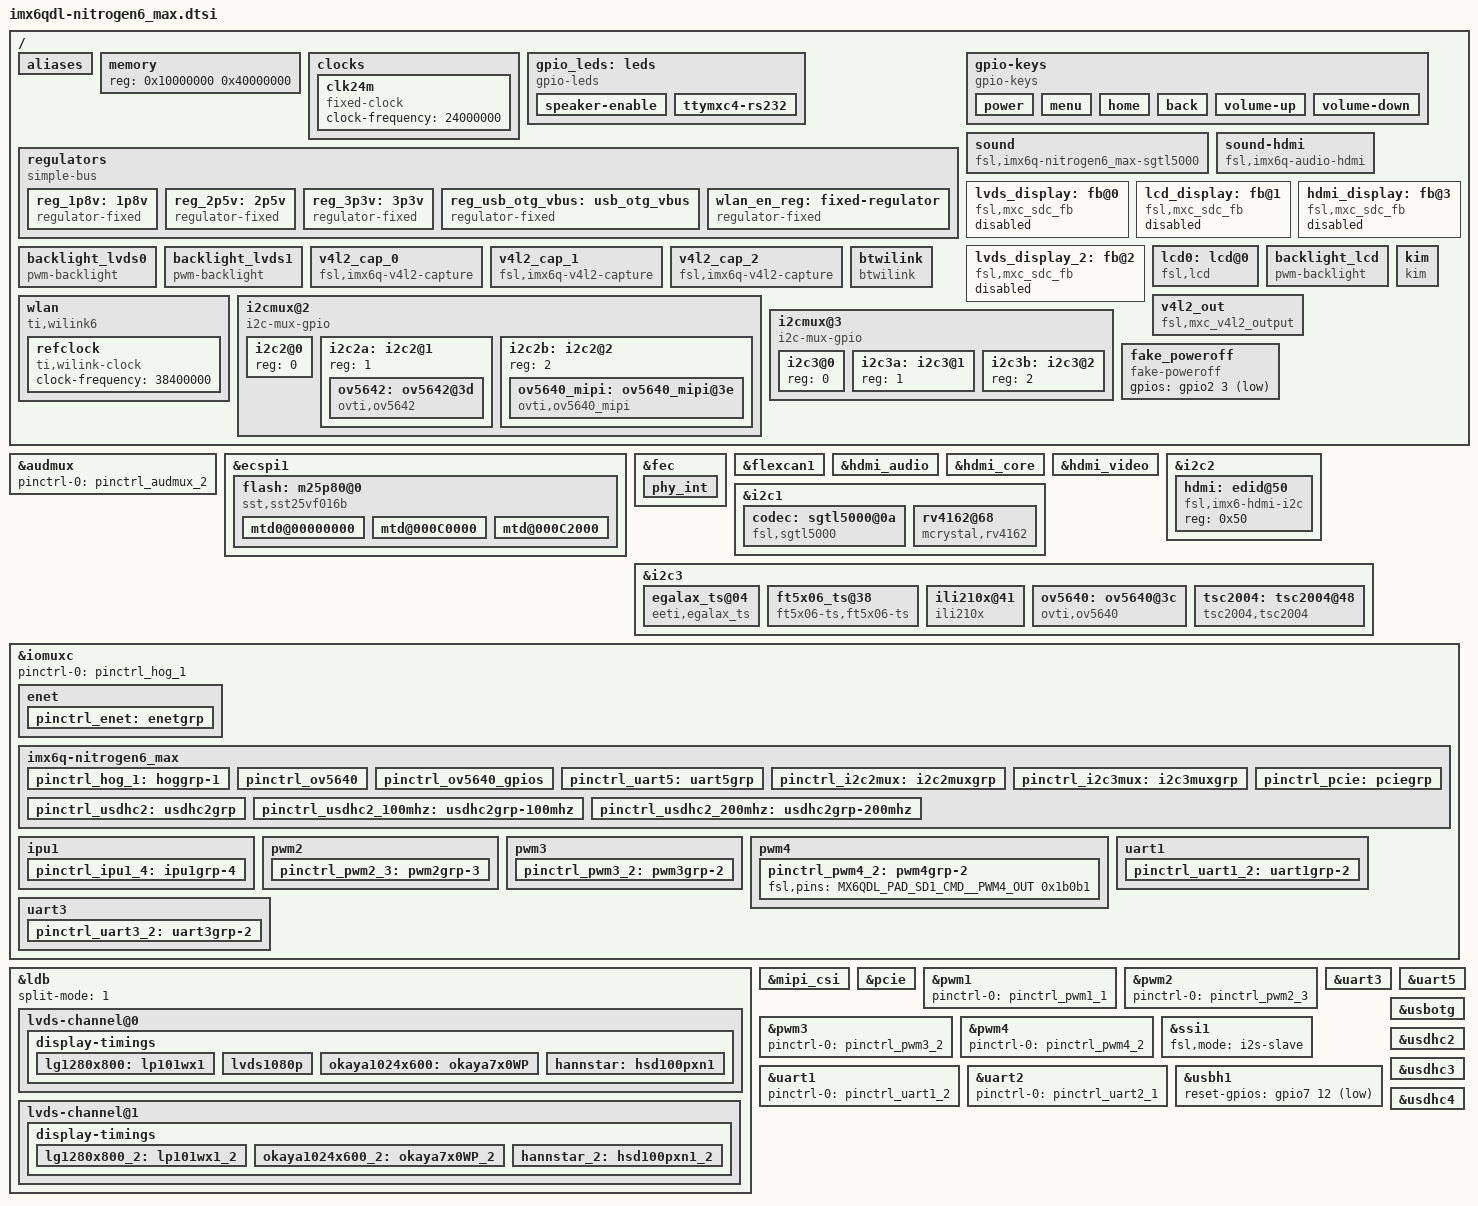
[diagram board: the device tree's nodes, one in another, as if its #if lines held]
/*
 * Copyright 2013 Boundary Devices
 * Copyright 2012 Freescale Semiconductor, Inc.
 * Copyright 2011 Linaro Ltd.
 *
 * The code contained herein is licensed under the GNU General Public
 * License. You may obtain a copy of the GNU General Public License
 * Version 2 or later at the following locations:
 *
 * http://www.opensource.org/licenses/gpl-license.html
 * http://www.gnu.org/copyleft/gpl.html
 */
#include <dt-bindings/input/input.h>

/ {
	aliases {
                mxcfb0 = &hdmi_display;
                mxcfb1 = &lvds_display;
                mxcfb2 = &lcd_display;
                mxcfb3 = &lvds_display_2;
		hdmi_display = &hdmi_display;
		lvds_display = &lvds_display;
		lcd_display = &lcd_display;
		hannstar = &hannstar ;
		lg1280x800 = &lg1280x800;
		lvds1080p = &lvds1080p;
		okaya1024x600 = &okaya1024x600;

		lvds_display_2 = &lvds_display_2;
		hannstar_2 = &hannstar_2 ;
		lg1280x800_2 = &lg1280x800_2;
		okaya1024x600_2 = &okaya1024x600_2;
		ldb = &ldb;
	};

	memory {
		reg = <0x10000000 0x40000000>;
	};

	clocks {
		clk24m: clk24m {
			compatible = "fixed-clock";
			#clock-cells = <0>;
			clock-frequency = <24000000>;
		};
	};

	gpio_leds: leds {
		compatible = "gpio-leds";
	};

	regulators {
		compatible = "simple-bus";

		reg_1p8v: 1p8v {
			compatible = "regulator-fixed";
			regulator-name = "1P8V";
			regulator-min-microvolt = <1800000>;
			regulator-max-microvolt = <1800000>;
			regulator-always-on;
		};

		reg_2p5v: 2p5v {
			compatible = "regulator-fixed";
			regulator-name = "2P5V";
			regulator-min-microvolt = <2500000>;
			regulator-max-microvolt = <2500000>;
			regulator-always-on;
		};

		reg_3p3v: 3p3v {
			compatible = "regulator-fixed";
			regulator-name = "3P3V";
			regulator-min-microvolt = <3300000>;
			regulator-max-microvolt = <3300000>;
			regulator-always-on;
		};

		reg_usb_otg_vbus: usb_otg_vbus {
			compatible = "regulator-fixed";
			regulator-name = "usb_otg_vbus";
			regulator-min-microvolt = <5000000>;
			regulator-max-microvolt = <5000000>;
			gpio = <&gpio3 22 0>;
			enable-active-high;
		};

		wlan_en_reg: fixed-regulator {
			compatible = "regulator-fixed";
			regulator-name = "wlan-en";
			regulator-min-microvolt = <3300000>;
			regulator-max-microvolt = <3300000>;

			gpio = <&gpio6 15 0>;
			startup-delay-us = <70000>;
			enable-active-high;
			debug;
		};
	};

	gpio-keys {
		compatible = "gpio-keys";
		power {
			label = "Power Button";
			gpios = <&gpio2 3 GPIO_ACTIVE_LOW>;
			linux,code = <KEY_POWER>;	/* or KEY_SEARCH */
			gpio-key,wakeup;
		};

		menu {
			label = "Menu";
			gpios = <&gpio2 1 GPIO_ACTIVE_LOW>;
			linux,code = <KEY_MENU>;
		};

		home {
			label = "Home";
			gpios = <&gpio2 4 GPIO_ACTIVE_LOW>;
			linux,code = <KEY_HOME>;
		};

		back {
			label = "Back";
			gpios = <&gpio2 2 GPIO_ACTIVE_LOW>;
			linux,code = <KEY_BACK>;
		};

		volume-up {
			label = "Volume Up";
			gpios = <&gpio7 13 GPIO_ACTIVE_LOW>;
			linux,code = <KEY_VOLUMEUP>;
		};

		volume-down {
			label = "Volume Down";
			gpios = <&gpio7 1 GPIO_ACTIVE_LOW>;
			linux,code = <KEY_VOLUMEDOWN>;
		};
	};

	sound {
		compatible = "fsl,imx6q-nitrogen6_max-sgtl5000",
			     "fsl,imx-audio-sgtl5000";
		model = "sgtl5000-audio";
		cpu-dai = <&ssi1>;
		audio-codec = <&codec>;
		audio-routing =
			"MIC_IN", "Mic Jack",
			"Mic Jack", "Mic Bias",
			"Headphone Jack", "HP_OUT";
		mux-int-port = <1>;
		mux-ext-port = <3>;
	};
	sound-hdmi {
		compatible = "fsl,imx6q-audio-hdmi",
			     "fsl,imx-audio-hdmi";
		model = "imx-audio-hdmi";
		hdmi-controller = <&hdmi_audio>;
	};

	lvds_display: fb@0 {
		compatible = "fsl,mxc_sdc_fb";
		disp_dev = "ldb";
		interface_pix_fmt = "RGB666";
		default_bpp = <16>;
		int_clk = <0>;
		late_init = <0>;
		status = "disabled";
	};

	lcd_display: fb@1 {
		compatible = "fsl,mxc_sdc_fb";
		disp_dev = "lcd";
		interface_pix_fmt = "RGB666";
		default_bpp = <16>;
		int_clk = <0>;
		late_init = <0>;
		status = "disabled";
	};

	lvds_display_2: fb@2 {
		compatible = "fsl,mxc_sdc_fb";
		disp_dev = "ldb";
		interface_pix_fmt = "RGB666";
		default_bpp = <16>;
		int_clk = <0>;
		late_init = <0>;
		status = "disabled";
	};

	hdmi_display: fb@3 {
		compatible = "fsl,mxc_sdc_fb";
		disp_dev = "hdmi";
		interface_pix_fmt = "RGB24";
		mode_str ="1280x720M@60";
		default_bpp = <24>;
		int_clk = <0>;
		late_init = <0>;
		status = "disabled";
	};

	lcd0: lcd@0 {
		compatible = "fsl,lcd";
		ipu_id = <0>;
		disp_id = <0>;
		default_ifmt = "RGB666";
		pinctrl-names = "default";
		pinctrl-0 = <&pinctrl_ipu1_4>;
		status = "okay";
	};

	backlight_lcd: backlight_lcd {
		compatible = "pwm-backlight";
		pwms = <&pwm1 0 5000000>;
		brightness-levels = <0 4 8 16 32 64 128 255>;
		default-brightness-level = <7>;
	};

	backlight_lvds0 {
		compatible = "pwm-backlight";
		pwms = <&pwm4 0 5000000>;
		brightness-levels = <0 4 8 16 32 64 128 255>;
		default-brightness-level = <7>;
	};

	backlight_lvds1: backlight_lvds1 {
		compatible = "pwm-backlight";
		pwms = <&pwm2 0 5000000>;
		brightness-levels = <0 4 8 16 32 64 128 255>;
		default-brightness-level = <7>;
	};

	v4l2_cap_0 {
		compatible = "fsl,imx6q-v4l2-capture";
		ipu_id = <0>;
		csi_id = <0>;
		mclk_source = <0>;
		status = "okay";
	};

	v4l2_cap_1 {
		compatible = "fsl,imx6q-v4l2-capture";
		ipu_id = <0>;
		csi_id = <1>;
		mipi_camera = <1>;
		mclk_source = <0>;
		status = "okay";
	};

	v4l2_cap_2: v4l2_cap_2 {
		compatible = "fsl,imx6q-v4l2-capture";
		ipu_id = <0>;
		csi_id = <1>;
		mclk_source = <0>;
		status = "okay";
	};

	v4l2_out {
		compatible = "fsl,mxc_v4l2_output";
		status = "okay";
	};
#ifdef CONFIG_WL_TI
	wlan {
		compatible = "ti,wilink6";
		interrupt-parent = <&gpio6>;
		interrupts = <11 IRQ_TYPE_LEVEL_HIGH>;
		clocks = <&refclock>;
		clock-names = "refclock";

		refclock: refclock {
			compatible = "ti,wilink-clock";
			#clock-cells = <0>;
			clock-frequency = <38400000>;
		};
	};

	btwilink {
		compatible = "btwilink";
	};

	kim {
		compatible = "kim";
		nshutdown_gpio = <&gpio6 16 0>;
		dev_name = "/dev/ttymxc2";
		flow_cntrl = <1>;
		baud_rate = <3000000>;
	};
#else
	bt_rfkill: bt_rfkill {
		compatible = "net,rfkill-gpio";
		name = "bt_rfkill";
		gpios = <&gpio6 16 0>;
		type = <2>;     /* bluetooth */
	};
#endif
	i2cmux@2 {
		compatible = "i2c-mux-gpio";
		pinctrl-names = "default";
		pinctrl-0 = <&pinctrl_i2c2mux>;
		#address-cells = <1>;
		#size-cells = <0>;
		mux-gpios = <&gpio3 20 0>, <&gpio4 15 0>;
		i2c-parent = <&i2c2>;
		idle-state = <0>;

		i2c2@0 {
			reg = <0>;
			#address-cells = <1>;
			#size-cells = <0>;
		};

		i2c2a: i2c2@1 {
			reg = <1>;
			#address-cells = <1>;
			#size-cells = <0>;
		};

		i2c2b: i2c2@2 {
			reg = <2>;
			#address-cells = <1>;
			#size-cells = <0>;
		};
	};

	i2cmux@3 {
		compatible = "i2c-mux-gpio";
		pinctrl-names = "default";
		pinctrl-0 = <&pinctrl_i2c3mux>;
		#address-cells = <1>;
		#size-cells = <0>;
		mux-gpios = <&gpio2 25 0>;
		i2c-parent = <&i2c3>;
		idle-state = <0>;

		i2c3@0 {
			reg = <0>;
			#address-cells = <1>;
			#size-cells = <0>;
		};

		i2c3a: i2c3@1 {
			reg = <1>;
			#address-cells = <1>;
			#size-cells = <0>;
		};

		i2c3b: i2c3@2 {
			reg = <2>;
			#address-cells = <1>;
			#size-cells = <0>;
		};
	};

	fake_poweroff {
		compatible = "fake-poweroff";
		gpios = <&gpio2 3 GPIO_ACTIVE_LOW>;
	};
};

&audmux {
	pinctrl-names = "default";
	pinctrl-0 = <&pinctrl_audmux_2>;
	status = "okay";
};

&ecspi1 {
	fsl,spi-num-chipselects = <1>;
	cs-gpios = <&gpio3 19 0>;
	pinctrl-names = "default";
	pinctrl-0 = <&pinctrl_ecspi1_1>;
	status = "okay";

	flash: m25p80@0 {
		compatible = "sst,sst25vf016b";
		spi-max-frequency = <20000000>;
		reg = <0>;
		#address-cells = <1>;
		#size-cells = <1>;
		mtd0@00000000 {
			label = "U-Boot";
			reg = <0x0 0xC0000>;
		};

		mtd@000C0000 {
			label = "env";
			reg = <0xC0000 0x2000>;
		};
		mtd@000C2000 {
			label = "splash";
			reg = <0xC2000 0x13e000>;
		};
	};
};

&fec {
	pinctrl-names = "default";
	pinctrl-0 = <&pinctrl_enet>;
	phy-mode = "rgmii";
#if 0
	phy-reset-gpios = <&gpio1 27 0>;
	status = "okay";
#endif
	interrupts-extended = <&gpio1 6 IRQ_TYPE_LEVEL_HIGH>,
			      <&intc 0 119 IRQ_TYPE_LEVEL_HIGH>;
	status = "okay";

	#address-cells = <0>;
	#size-cells = <1>;
	phy_int {
		reg = <0x6>;
		interrupt-parent = <&gpio1>;
		interrupts = <28 IRQ_TYPE_LEVEL_LOW>;
	};
};

&flexcan1 {
	pinctrl-names = "default";
	pinctrl-0 = <&pinctrl_flexcan1_1>;
	trx-stby-gpio = <&gpio1 2 GPIO_ACTIVE_LOW>;
	status = "okay";
};

&gpio_leds {
	speaker-enable {
		gpios = <&gpio1 29 GPIO_ACTIVE_HIGH>;
		retain-state-suspended;
		default-state = "off";
	};
	ttymxc4-rs232 {
		gpios = <&gpio6 10 GPIO_ACTIVE_HIGH>;
		retain-state-suspended;
		default-state = "on";
	};
};

&hdmi_audio {
	status = "okay";
};

&hdmi_core {
	ipu_id = <1>;
	disp_id = <0>;
	status = "okay";
};

&hdmi_video {
	fsl,phy_reg_vlev = <0x0294>;
	fsl,phy_reg_cksymtx = <0x800d>;
	status = "okay";
};

&i2c1 {
	clock-frequency = <100000>;
	pinctrl-names = "default";
	pinctrl-0 = <&pinctrl_i2c1_1>;
	status = "okay";

	codec: sgtl5000@0a {
		compatible = "fsl,sgtl5000";
		reg = <0x0a>;
		clocks = <&clks 201>;
		VDDA-supply = <&reg_2p5v>;
		VDDIO-supply = <&reg_3p3v>;
	};
	rv4162@68 {
		compatible = "mcrystal,rv4162";
		reg = <0x68>;
		interrupt-parent = <&gpio4>;
		interrupts = <6 IRQ_TYPE_LEVEL_LOW>;
	};
};

&i2c2 {
	clock-frequency = <100000>;
	pinctrl-names = "default";
	pinctrl-0 = <&pinctrl_i2c2_2>;
	status = "okay";

	hdmi: edid@50 {
		compatible = "fsl,imx6-hdmi-i2c";
		reg = <0x50>;
	};
};

&i2c2a {
	ov5642: ov5642@3d {
		compatible = "ovti,ov5642";
		reg = <0x3d>;
		pinctrl-names = "default";
		pinctrl-0 = <&pinctrl_ipu1_2>;
		clocks = <&clks 200>;
		clock-names = "csi_mclk";
		DOVDD-supply = <&reg_1p8v>;
		AVDD-supply = <&reg_2p5v>;
		DVDD-supply = <&reg_1p8v>;
		pwn-gpios = <&gpio3 29 1>;
		rst-gpios = <&gpio1 4 0>;
		ipu_id = <0>;
		csi_id = <0>;
		mclk = <24000000>;
		mclk_source = <0>;
	};
};

&i2c2b {
	ov5640_mipi: ov5640_mipi@3e {
		compatible = "ovti,ov5640_mipi";
		reg = <0x3e>;
		clocks = <&clks 147>;
		clock-names = "csi_mclk";
		DOVDD-supply = <&reg_1p8v>;
		AVDD-supply = <&reg_2p5v>;
		DVDD-supply = <&reg_1p8v>;
		pwn-gpios = <&gpio6 9 1>;
		rst-gpios = <&gpio2 5 0>;
		ipu_id = <0>;
		csi_id = <1>;
		mclk = <22000000>;
		mclk_source = <0>;
		pwms = <&pwm3 0 45>;
	};
};

&i2c3 {
        clock-frequency = <100000>;
        pinctrl-names = "default";
        pinctrl-0 = <&pinctrl_i2c3_3>;
        status = "okay";

        egalax_ts@04 {
                compatible = "eeti,egalax_ts";
                reg = <0x04>;
                interrupt-parent = <&gpio1>;
                interrupts = <9 2>;
                wakeup-gpios = <&gpio1 9 0>;
        };

        ft5x06_ts@38 {
		compatible = "ft5x06-ts,ft5x06-ts";
		reg = <0x38>;
		interrupt-parent = <&gpio1>;
		interrupts = <9 2>;
		wakeup-gpios = <&gpio1 9 0>;
	};

        ili210x@41 {
		compatible = "ili210x";
		reg = <0x41>;
		interrupt-parent = <&gpio1>;
		interrupts = <9 2>;
		wakeup-gpios = <&gpio1 9 0>;
	};

	ov5640: ov5640@3c {
		compatible = "ovti,ov5640";
		reg = <0x3c>;
		pinctrl-names = "default";
		pinctrl-0 = <&pinctrl_ov5640 &pinctrl_ov5640_gpios>;
		clocks = <&clk24m 0>;
		clock-names = "csi_mclk";
		DOVDD-supply = <&reg_1p8v>;
		AVDD-supply = <&reg_2p5v>;
		DVDD-supply = <&reg_1p8v>;
		pwn-gpios = <&gpio3 13 1>;
		rst-gpios = <&gpio3 14 0>;
		csi_id = <1>;
		mclk = <24000000>;
		mclk_source = <0>;
	};

	tsc2004: tsc2004@48 {
		compatible = "tsc2004,tsc2004";
		reg = <0x48>;
		interrupt-parent = <&gpio4>;
		interrupts = <20 2>;
		wakeup-gpios = <&gpio4 20 0>;
	};
};

&iomuxc {
	pinctrl-names = "default";
	pinctrl-0 = <&pinctrl_hog_1>;

	enet {
		pinctrl_enet: enetgrp {
			fsl,pins = <
				MX6QDL_PAD_ENET_MDIO__ENET_MDIO		0x1b0b0
				MX6QDL_PAD_ENET_MDC__ENET_MDC		0x1b0b0
				MX6QDL_PAD_RGMII_TXC__RGMII_TXC		0x1b0b0
				MX6QDL_PAD_RGMII_TD0__RGMII_TD0		0x1b0b0
				MX6QDL_PAD_RGMII_TD1__RGMII_TD1		0x1b0b0
				MX6QDL_PAD_RGMII_TD2__RGMII_TD2		0x1b0b0
				MX6QDL_PAD_RGMII_TD3__RGMII_TD3		0x1b0b0
				MX6QDL_PAD_RGMII_TX_CTL__RGMII_TX_CTL	0x1b0b0
				MX6QDL_PAD_ENET_REF_CLK__ENET_TX_CLK	0x1b0b0
				MX6QDL_PAD_RGMII_RXC__RGMII_RXC		0x1b0b0
				MX6QDL_PAD_RGMII_RD0__RGMII_RD0		0x1b0b0
				MX6QDL_PAD_RGMII_RD1__RGMII_RD1		0x1b0b0
				MX6QDL_PAD_RGMII_RD2__RGMII_RD2		0x1b0b0
				MX6QDL_PAD_RGMII_RD3__RGMII_RD3		0x1b0b0
				MX6QDL_PAD_RGMII_RX_CTL__RGMII_RX_CTL	0x1b0b0
				MX6QDL_PAD_ENET_RXD0__GPIO1_IO27	0x0f0b0		/* ethernet phy reset */
				MX6QDL_PAD_ENET_TX_EN__GPIO1_IO28	0x1b0b0		/* ethernet phy interrupt */
				MX6QDL_PAD_GPIO_6__ENET_IRQ		0x000b1
			>;
		};
	};

	imx6q-nitrogen6_max {
		pinctrl_hog_1: hoggrp-1 {
			fsl,pins = <
				/* Power Button */
                                MX6QDL_PAD_NANDF_D3__GPIO2_IO03         0x1b0b0
                                /* Menu Button */
                                MX6QDL_PAD_NANDF_D1__GPIO2_IO01         0x1b0b0
                                /* Home Button */
                                MX6QDL_PAD_NANDF_D4__GPIO2_IO04         0x1b0b0
                                /* Back Button */
                                MX6QDL_PAD_NANDF_D2__GPIO2_IO02         0x1b0b0
                                /* Volume Up Button */
                                MX6QDL_PAD_GPIO_18__GPIO7_IO13          0x1b0b0
                                /* Volume Down Button */
                                MX6QDL_PAD_SD3_DAT4__GPIO7_IO01         0x1b0b0
				MX6QDL_PAD_EIM_D19__GPIO3_IO19		0x80000000	/* spi-nor CS */
				MX6QDL_PAD_EIM_D22__GPIO3_IO22		0x80000000	/* otg power en */
				MX6QDL_PAD_SD3_DAT5__GPIO7_IO00		0x80000000	/* USDHC3 CD */
				MX6QDL_PAD_GPIO_0__CCM_CLKO1		0x000b0		/* SGTL5000 sys_mclk */
				MX6QDL_PAD_ENET_TXD1__GPIO1_IO29	0x1b0b0		/* SGTL5000 amplifier mute, weak pull-up */
				MX6QDL_PAD_GPIO_2__GPIO1_IO02		0x80000000	/* CAN standby */
				MX6QDL_PAD_GPIO_9__GPIO1_IO09		0x80000000	/* I2C3 touch screen interrupt */
				MX6QDL_PAD_DI0_PIN4__GPIO4_IO20		0x1b0b0		/* tsc2004 interrupt */
				MX6QDL_PAD_NANDF_WP_B__GPIO6_IO09	0x0b0b0		/* ov5640 mipi powerdown */
				MX6QDL_PAD_NANDF_D5__GPIO2_IO05		0x000b0		/* ov5640 mipi reset */
				MX6QDL_PAD_GPIO_3__CCM_CLKO2		0x000b0		/* ov5642 mclk */
				MX6QDL_PAD_EIM_D29__GPIO3_IO29		0x000b0		/* ov5642 Power Down */
				MX6QDL_PAD_GPIO_4__GPIO1_IO04		0x000b0		/* ov5642 Reset */
				MX6QDL_PAD_GPIO_17__GPIO7_IO12		0x0b0b0		/* USB Hub Reset */
				MX6QDL_PAD_NANDF_CS1__SD3_VSELECT	0x100b0		/* sd3 voltage select */
				MX6QDL_PAD_NANDF_CS3__GPIO6_IO16	0x000b0		/* wl12xx_bt_en */
				MX6QDL_PAD_KEY_COL0__GPIO4_IO06		0x1b0b0		/* rv4162 rtc interrupt */
			>;
		};

		pinctrl_ov5640: pinctrl_ov5640 {
			/* parallel camera on CSI1, pins differ for iMX6Q/iMX6DL */
		};

		pinctrl_ov5640_gpios: pinctrl_ov5640_gpios {
			fsl,pins = <
				MX6QDL_PAD_EIM_DA13__GPIO3_IO13		0x0b0b0		/* Power */
				MX6QDL_PAD_EIM_DA14__GPIO3_IO14		0x030b0		/* Reset */
			>;
		};

		pinctrl_uart5: uart5grp {
			fsl,pins = <
				MX6QDL_PAD_KEY_ROW1__UART5_RX_DATA	0x130b1
				MX6QDL_PAD_KEY_COL1__UART5_TX_DATA	0x030b1
				MX6QDL_PAD_NANDF_RB0__GPIO6_IO10	0x1b0b1		/* RS485 RX Enable: pull up */
				MX6QDL_PAD_NANDF_CLE__GPIO6_IO07	0x030b1		/* RS485 DEN: pull down */
				MX6QDL_PAD_EIM_CS1__GPIO2_IO24		0x030b1		/* RS485/!RS232 Select: pull down (rs232) */
				MX6QDL_PAD_NANDF_ALE__GPIO6_IO08	0x030b1		/* ON: pull down */
			>;
		};

		pinctrl_i2c2mux: i2c2muxgrp {
			fsl,pins = <
				MX6QDL_PAD_EIM_D20__GPIO3_IO20		0x000b0		/* ov5642 camera i2c enable */
				MX6QDL_PAD_KEY_ROW4__GPIO4_IO15		0x000b0		/* ov5640_mipi camera i2c enable */
			>;
		};
		pinctrl_i2c3mux: i2c3muxgrp {
			fsl,pins = <
				MX6QDL_PAD_EIM_OE__GPIO2_IO25		0x000b0		/* pcie i2c enable */
			>;
		};
		pinctrl_pcie: pciegrp {
			fsl,pins = <
				MX6QDL_PAD_EIM_BCLK__GPIO6_IO31		0x000b0		/* pcie reset */
			>;
		};

		pinctrl_usdhc2: usdhc2grp {
			fsl,pins = <
				MX6QDL_PAD_SD2_CLK__SD2_CLK		0x10071
				MX6QDL_PAD_SD2_CMD__SD2_CMD		0x17071
				MX6QDL_PAD_SD2_DAT0__SD2_DATA0		0x17071
				MX6QDL_PAD_SD2_DAT1__SD2_DATA1		0x17071
				MX6QDL_PAD_SD2_DAT2__SD2_DATA2		0x17071
				MX6QDL_PAD_SD2_DAT3__SD2_DATA3		0x17071
				MX6QDL_PAD_SD1_CLK__OSC32K_32K_OUT	0x000b0		/* slow clock */
				MX6QDL_PAD_NANDF_CS0__GPIO6_IO11	0x100b0		/* wl12xx_wl_irq */
				MX6QDL_PAD_NANDF_CS2__GPIO6_IO15	0x000b0		/* wl12xx_wl_en */
			>;
		};

		pinctrl_usdhc2_100mhz: usdhc2grp-100mhz {
			fsl,pins = <
				MX6QDL_PAD_SD2_CMD__SD2_CMD		0x170B9
				MX6QDL_PAD_SD2_CLK__SD2_CLK		0x100B9
				MX6QDL_PAD_SD2_DAT0__SD2_DATA0		0x170B9
				MX6QDL_PAD_SD2_DAT1__SD2_DATA1 		0x170B9
				MX6QDL_PAD_SD2_DAT2__SD2_DATA2 		0x170B9
				MX6QDL_PAD_SD2_DAT3__SD2_DATA3 		0x170B9
			>;
		};

		pinctrl_usdhc2_200mhz: usdhc2grp-200mhz {
			fsl,pins = <
				MX6QDL_PAD_SD2_CMD__SD2_CMD		0x170F9
				MX6QDL_PAD_SD2_CLK__SD2_CLK 		0x100F9
				MX6QDL_PAD_SD2_DAT0__SD2_DATA0		0x170F9
				MX6QDL_PAD_SD2_DAT1__SD2_DATA1 		0x170F9
				MX6QDL_PAD_SD2_DAT2__SD2_DATA2 		0x170F9
				MX6QDL_PAD_SD2_DAT3__SD2_DATA3 		0x170F9
			>;
		};
	};

	ipu1 {
		pinctrl_ipu1_4: ipu1grp-4 {
			fsl,pins = <
				MX6QDL_PAD_DI0_DISP_CLK__IPU1_DI0_DISP_CLK 0x10
				MX6QDL_PAD_DI0_PIN15__IPU1_DI0_PIN15       0x10
				MX6QDL_PAD_DI0_PIN2__IPU1_DI0_PIN02        0x10
				MX6QDL_PAD_DI0_PIN3__IPU1_DI0_PIN03        0x10
				MX6QDL_PAD_DISP0_DAT0__IPU1_DISP0_DATA00   0x10
				MX6QDL_PAD_DISP0_DAT1__IPU1_DISP0_DATA01   0x10
				MX6QDL_PAD_DISP0_DAT2__IPU1_DISP0_DATA02   0x10
				MX6QDL_PAD_DISP0_DAT3__IPU1_DISP0_DATA03   0x10
				MX6QDL_PAD_DISP0_DAT4__IPU1_DISP0_DATA04   0x10
				MX6QDL_PAD_DISP0_DAT5__IPU1_DISP0_DATA05   0x10
				MX6QDL_PAD_DISP0_DAT6__IPU1_DISP0_DATA06   0x10
				MX6QDL_PAD_DISP0_DAT7__IPU1_DISP0_DATA07   0x10
				MX6QDL_PAD_DISP0_DAT8__IPU1_DISP0_DATA08   0x10
				MX6QDL_PAD_DISP0_DAT9__IPU1_DISP0_DATA09   0x10
				MX6QDL_PAD_DISP0_DAT10__IPU1_DISP0_DATA10  0x10
				MX6QDL_PAD_DISP0_DAT11__IPU1_DISP0_DATA11  0x10
				MX6QDL_PAD_DISP0_DAT12__IPU1_DISP0_DATA12  0x10
				MX6QDL_PAD_DISP0_DAT13__IPU1_DISP0_DATA13  0x10
				MX6QDL_PAD_DISP0_DAT14__IPU1_DISP0_DATA14  0x10
				MX6QDL_PAD_DISP0_DAT15__IPU1_DISP0_DATA15  0x10
				MX6QDL_PAD_DISP0_DAT16__IPU1_DISP0_DATA16  0x10
				MX6QDL_PAD_DISP0_DAT17__IPU1_DISP0_DATA17  0x10
				MX6QDL_PAD_DISP0_DAT18__IPU1_DISP0_DATA18  0x10
				MX6QDL_PAD_DISP0_DAT19__IPU1_DISP0_DATA19  0x10
				MX6QDL_PAD_DISP0_DAT20__IPU1_DISP0_DATA20  0x10
				MX6QDL_PAD_DISP0_DAT21__IPU1_DISP0_DATA21  0x10
				MX6QDL_PAD_DISP0_DAT22__IPU1_DISP0_DATA22  0x10
				MX6QDL_PAD_DISP0_DAT23__IPU1_DISP0_DATA23  0x10
			>;
		};
	};

	pwm2 {
		pinctrl_pwm2_3: pwm2grp-3 {
			fsl,pins = <
				MX6QDL_PAD_SD1_DAT2__PWM2_OUT 0x1b0b1
			>;
		};
	};

	pwm3 {
		pinctrl_pwm3_2: pwm3grp-2 {
			fsl,pins = <
				MX6QDL_PAD_SD1_DAT1__PWM3_OUT 0x1b0b1
			>;
		};
	};

	pwm4 {
		pinctrl_pwm4_2: pwm4grp-2 {
			fsl,pins = <
				MX6QDL_PAD_SD1_CMD__PWM4_OUT 0x1b0b1
			>;
		};
	};

	uart1 {
		pinctrl_uart1_2: uart1grp-2 {
			fsl,pins = <
				MX6QDL_PAD_SD3_DAT7__UART1_TX_DATA 0x1b0b1
				MX6QDL_PAD_SD3_DAT6__UART1_RX_DATA 0x1b0b1
			>;
		};
	};

	uart3 {
		pinctrl_uart3_2: uart3grp-2 {
			fsl,pins = <
				MX6QDL_PAD_EIM_D25__UART3_RX_DATA 0x1b0b1
				MX6QDL_PAD_EIM_D24__UART3_TX_DATA 0x1b0b1
				MX6QDL_PAD_EIM_D23__UART3_CTS_B   0x1b0b1
				MX6QDL_PAD_EIM_D31__UART3_RTS_B   0x1b0b1
			>;
		};
	};
};

&ldb {
	split-mode = <1>;
	status = "okay";

	lvds-channel@0 {
		crtc = "ipu1-di1";
		fsl,data-mapping = "spwg";
		fsl,data-width = <18>;
		status = "okay";
		primary;

		display-timings {
			lg1280x800: lp101wx1 {
				clock-frequency = <72000000>;
				hactive = <1280>;
				vactive = <800>;
				hback-porch = <48>;
				hfront-porch = <80>;
				vback-porch = <15>;
				vfront-porch = <2>;
				hsync-len = <32>;
				vsync-len = <6>;
			};
			lvds1080p: lvds1080p {
				clock-frequency = <148500000>;
				hactive = <1920>;
				vactive = <1080>;
				hback-porch = <148>;
				hfront-porch = <88>;
				vback-porch = <36>;
				vfront-porch = <4>;
				hsync-len = <44>;
				vsync-len = <5>;
			};
			okaya1024x600: okaya7x0WP {
				clock-frequency = <52000000>;
				hactive = <1024>;
				vactive = <600>;
				hback-porch = <220>;
				hfront-porch = <40>;
				vback-porch = <7>;
				vfront-porch = <21>;
				hsync-len = <60>;
				vsync-len = <10>;
			};
			hannstar: hsd100pxn1 {
				clock-frequency = <65000000>;
				hactive = <1024>;
				vactive = <768>;
				hback-porch = <220>;
				hfront-porch = <40>;
				vback-porch = <21>;
				vfront-porch = <7>;
				hsync-len = <60>;
				vsync-len = <10>;
			};
		};
	};

	lvds-channel@1 {
		crtc = "ipu1-di0";
		fsl,data-mapping = "spwg";
		fsl,data-width = <18>;
		status = "okay";

		display-timings {
			lg1280x800_2: lp101wx1_2 {
				clock-frequency = <72000000>;
				hactive = <1280>;
				vactive = <800>;
				hback-porch = <48>;
				hfront-porch = <80>;
				vback-porch = <15>;
				vfront-porch = <2>;
				hsync-len = <32>;
				vsync-len = <6>;
			};
			okaya1024x600_2: okaya7x0WP_2 {
				clock-frequency = <52000000>;
				hactive = <1024>;
				vactive = <600>;
				hback-porch = <220>;
				hfront-porch = <40>;
				vback-porch = <7>;
				vfront-porch = <21>;
				hsync-len = <60>;
				vsync-len = <10>;
			};
			hannstar_2: hsd100pxn1_2 {
				clock-frequency = <65000000>;
				hactive = <1024>;
				vactive = <768>;
				hback-porch = <220>;
				hfront-porch = <40>;
				vback-porch = <21>;
				vfront-porch = <7>;
				hsync-len = <60>;
				vsync-len = <10>;
			};
		};
	};
};

&mipi_csi {
	ipu_id = <0>;
	csi_id = <1>;
	v_channel = <0>;
	lanes = <2>;
	status = "okay";
};

&pcie {
	pinctrl-names = "default";
	pinctrl-0 = <&pinctrl_pcie>;
	reset-gpio = <&gpio6 31 GPIO_ACTIVE_LOW>;
	status = "okay";
};

&pwm1 {
	pinctrl-names = "default";
	pinctrl-0 = <&pinctrl_pwm1_1>;
	status = "okay";
};

&pwm2 {
	pinctrl-names = "default";
	pinctrl-0 = <&pinctrl_pwm2_3>;
	status = "okay";
};

&pwm3 {
	pinctrl-names = "default";
	pinctrl-0 = <&pinctrl_pwm3_2>;
	status = "okay";
};

&pwm4 {
	pinctrl-names = "default";
	pinctrl-0 = <&pinctrl_pwm4_2>;
	status = "okay";
};

&ssi1 {
	fsl,mode = "i2s-slave";
	status = "okay";
};

&uart1 {
	pinctrl-names = "default";
	pinctrl-0 = <&pinctrl_uart1_2>;
	status = "okay";
};

&uart2 {
	pinctrl-names = "default";
	pinctrl-0 = <&pinctrl_uart2_1>;
	status = "okay";
};

&uart3 {
	pinctrl-names = "default";
	pinctrl-0 = <&pinctrl_uart3_2>;
	fsl,uart-has-rtscts;
	status = "okay";
};

&uart5 {
	pinctrl-names = "default";
	pinctrl-0 = <&pinctrl_uart5>;
	fsl,uart-has-rtscts;
	status = "okay";
};

&usbh1 {
	reset-gpios = <&gpio7 12 GPIO_ACTIVE_LOW>;
	status = "okay";
};

&usbotg {
	vbus-supply = <&reg_usb_otg_vbus>;
	pinctrl-names = "default";
	pinctrl-0 = <&pinctrl_usbotg_1>;
	disable-over-current;
	status = "okay";
};

&usdhc2 {	/* uSDHC2, TiWi wl1271 */
	pinctrl-names = "default", "state_100mhz", "state_200mhz";
	pinctrl-0 = <&pinctrl_usdhc2>;
	pinctrl-1 = <&pinctrl_usdhc2_100mhz>;
	pinctrl-2 = <&pinctrl_usdhc2_200mhz>;
	bus-width = <4>;
	non-removable;
	vmmc-supply = <&wlan_en_reg>;
	vqmmc-1-8-v;
	ocr-limit = <0x80>;     /* 1.65v - 1.95v */
	cap-power-off-card;
	keep-power-in-suspend;
	status = "okay";
};

&usdhc3 {
	pinctrl-names = "default";
	pinctrl-0 = <&pinctrl_usdhc3_2>;
	bus-width = <4>;
	cd-gpios = <&gpio7 0 0>;
	vmmc-supply = <&reg_3p3v>;
	status = "okay";
};

&usdhc4 {
	pinctrl-names = "default";
	pinctrl-0 = <&pinctrl_usdhc4_1>;
	bus-width = <8>;
	non-removable;
	vqmmc-1-8-v;
	vmmc-supply = <&reg_1p8v>;
	ocr-limit = <0x80>;     /* 1.65v - 1.95v */
	keep-power-in-suspend;
	status = "okay";
};
